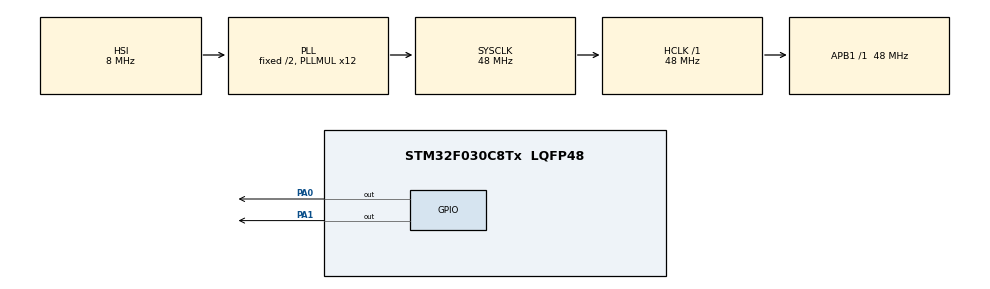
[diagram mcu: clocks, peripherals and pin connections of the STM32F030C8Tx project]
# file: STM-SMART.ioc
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Mcu.Family=STM32F0
Mcu.Name=STM32F030C8Tx
Mcu.Package=LQFP48
PA0.GPIO_Speed=GPIO_SPEED_FREQ_HIGH
PA0.Signal=GPIO_Output
PA1.GPIO_Speed=GPIO_SPEED_FREQ_HIGH
PA1.Signal=GPIO_Output
PA13.Mode=Serial_Wire
PA13.Signal=SYS_SWDIO
PA14.Mode=Serial_Wire
PA14.Signal=SYS_SWCLK
PF0-OSC_IN.Mode=HSE-External-Oscillator
PF0-OSC_IN.Signal=RCC_OSC_IN
PF1-OSC_OUT.Mode=HSE-External-Oscillator
PF1-OSC_OUT.Signal=RCC_OSC_OUT
ProjectManager.HeapSize=0x200
ProjectManager.StackSize=0x400
ProjectManager.TargetToolchain=STM32CubeIDE
RCC.AHBFreq_Value=48000000
RCC.APB1Freq_Value=48000000
RCC.APB1TimFreq_Value=48000000
RCC.HCLKFreq_Value=48000000
RCC.PLLMUL=RCC_PLL_MUL12
RCC.SYSCLKFreq_VALUE=48000000
RCC.SYSCLKSource=RCC_SYSCLKSOURCE_PLLCLK
VP_TIM3_VS_ClockSourceINT.Mode=Internal
board=custom

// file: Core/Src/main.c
/* USER CODE BEGIN Header */
/**
  ******************************************************************************
  * @file           : main.c
  * @brief          : Main program body
  ******************************************************************************
  * @attention
  *
  * Copyright (c) 2026 STMicroelectronics.
  * All rights reserved.
  *
  * This software is licensed under terms that can be found in the LICENSE file
  * in the root directory of this software component.
  * If no LICENSE file comes with this software, it is provided AS-IS.
  *
  ******************************************************************************
  */
/* USER CODE END Header */
#include "main.h"

TIM_HandleTypeDef htim3;

void SystemClock_Config(void);
static void MX_GPIO_Init(void);
static void MX_TIM3_Init(void);

/* USER CODE BEGIN 0 */
void delay_us(uint16_t us)
{
    __HAL_TIM_SET_COUNTER(&htim3, 0);
    while (__HAL_TIM_GET_COUNTER(&htim3) < us);
}
/* USER CODE END 0 */

int main(void)
{

  /* MCU Configuration--------------------------------------------------------*/

  /* Reset of all peripherals, Initializes the Flash interface and the Systick. */
  HAL_Init();

  /* Configure the system clock */
  SystemClock_Config();

  /* Initialize all configured peripherals */
  MX_GPIO_Init();
  MX_TIM3_Init();
  /* USER CODE BEGIN 2 */
  HAL_TIM_Base_Start(&htim3);
  /* USER CODE END 2 */

  /* Infinite loop */
  while (1)
  {

	  /* USER CODE BEGIN 3 */
	      /* فاز اول: تحریک مثبت به مدت 250 میکروثانیه */
	      HAL_GPIO_WritePin(GPIOA, GPIO_PIN_0, GPIO_PIN_SET);
	      delay_us(250);
	      HAL_GPIO_WritePin(GPIOA, GPIO_PIN_0, GPIO_PIN_RESET);

	      /* زمان مرده برای جلوگیری از شورت در پل H */
	      delay_us(40);

	      /* فاز دوم: تحریک منفی به مدت 250 میکروثانیه */
	      HAL_GPIO_WritePin(GPIOA, GPIO_PIN_1, GPIO_PIN_SET);
	      delay_us(250);
	      HAL_GPIO_WritePin(GPIOA, GPIO_PIN_1, GPIO_PIN_RESET);

	      /* زمان خاموشی تا تکمیل دوره تناوب 40 میلی‌ثانیه‌ای (فرکانس 25 هرتز) */
	      HAL_Delay(32);
	      delay_us(800);
	    }
	    /* USER CODE END 3 */
}

void SystemClock_Config(void)
{
  RCC_OscInitTypeDef RCC_OscInitStruct = {0};
  RCC_ClkInitTypeDef RCC_ClkInitStruct = {0};

  /** Initializes the RCC Oscillators according to the specified parameters
  * in the RCC_OscInitTypeDef structure.
  */
  RCC_OscInitStruct.OscillatorType = RCC_OSCILLATORTYPE_HSI;
  RCC_OscInitStruct.HSIState = RCC_HSI_ON;
  RCC_OscInitStruct.HSICalibrationValue = RCC_HSICALIBRATION_DEFAULT;
  RCC_OscInitStruct.PLL.PLLState = RCC_PLL_ON;
  RCC_OscInitStruct.PLL.PLLSource = RCC_PLLSOURCE_HSI;
  RCC_OscInitStruct.PLL.PLLMUL = RCC_PLL_MUL12;
  RCC_OscInitStruct.PLL.PREDIV = RCC_PREDIV_DIV1;
  if (HAL_RCC_OscConfig(&RCC_OscInitStruct) != HAL_OK)
  {
    Error_Handler();
  }

  /** Initializes the CPU, AHB and APB buses clocks
  */
  RCC_ClkInitStruct.ClockType = RCC_CLOCKTYPE_HCLK|RCC_CLOCKTYPE_SYSCLK
                              |RCC_CLOCKTYPE_PCLK1;
  RCC_ClkInitStruct.SYSCLKSource = RCC_SYSCLKSOURCE_PLLCLK;
  RCC_ClkInitStruct.AHBCLKDivider = RCC_SYSCLK_DIV1;
  RCC_ClkInitStruct.APB1CLKDivider = RCC_HCLK_DIV1;

  if (HAL_RCC_ClockConfig(&RCC_ClkInitStruct, FLASH_LATENCY_1) != HAL_OK)
  {
    Error_Handler();
  }
}

static void MX_TIM3_Init(void)
{

  TIM_ClockConfigTypeDef sClockSourceConfig = {0};
  TIM_MasterConfigTypeDef sMasterConfig = {0};

  htim3.Instance = TIM3;
  htim3.Init.Prescaler = 47;
  htim3.Init.CounterMode = TIM_COUNTERMODE_UP;
  htim3.Init.Period = 65535;
  htim3.Init.ClockDivision = TIM_CLOCKDIVISION_DIV1;
  htim3.Init.AutoReloadPreload = TIM_AUTORELOAD_PRELOAD_DISABLE;
  if (HAL_TIM_Base_Init(&htim3) != HAL_OK)
  {
    Error_Handler();
  }
  sClockSourceConfig.ClockSource = TIM_CLOCKSOURCE_INTERNAL;
  if (HAL_TIM_ConfigClockSource(&htim3, &sClockSourceConfig) != HAL_OK)
  {
    Error_Handler();
  }
  sMasterConfig.MasterOutputTrigger = TIM_TRGO_RESET;
  sMasterConfig.MasterSlaveMode = TIM_MASTERSLAVEMODE_DISABLE;
  if (HAL_TIMEx_MasterConfigSynchronization(&htim3, &sMasterConfig) != HAL_OK)
  {
    Error_Handler();
  }

}

static void MX_GPIO_Init(void)
{
  GPIO_InitTypeDef GPIO_InitStruct = {0};

  /* GPIO Ports Clock Enable */
  __HAL_RCC_GPIOF_CLK_ENABLE();
  __HAL_RCC_GPIOA_CLK_ENABLE();

  /*Configure GPIO pin Output Level */
  HAL_GPIO_WritePin(GPIOA, GPIO_PIN_0|GPIO_PIN_1, GPIO_PIN_RESET);

  /*Configure GPIO pins : PA0 PA1 */
  GPIO_InitStruct.Pin = GPIO_PIN_0|GPIO_PIN_1;
  GPIO_InitStruct.Mode = GPIO_MODE_OUTPUT_PP;
  GPIO_InitStruct.Pull = GPIO_NOPULL;
  GPIO_InitStruct.Speed = GPIO_SPEED_FREQ_HIGH;
  HAL_GPIO_Init(GPIOA, &GPIO_InitStruct);

}

void Error_Handler(void)
{
  __disable_irq();
  while (1)
  {
  }
}
